AUTOSAR XML (schema 4-0-3)
standard types defined: UInt8
package /AUTOSAR_Platform/DataConstrs
  range DC_UInt8: raw 0..255
package /PATAC/MSM/ComponentTypes
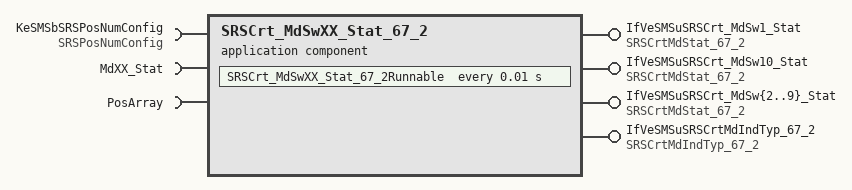
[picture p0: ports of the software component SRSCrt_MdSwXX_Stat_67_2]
  application sw component type SRSCrt_MdSwXX_Stat_67_2
    11 x provide port:
      IfVeSMSuSRSCrt_MdSw1_Stat: nonqueued-sender-com-spec=data-element=SRSCrtMdStat_67_2/Val, provided-interface=SRSCrtMdStat_67_2
      IfVeSMSuSRSCrt_MdSw10_Stat: nonqueued-sender-com-spec=data-element=SRSCrtMdStat_67_2/Val, provided-interface=SRSCrtMdStat_67_2
      IfVeSMSuSRSCrt_MdSw{2..9}_Stat: nonqueued-sender-com-spec=data-element=SRSCrtMdStat_67_2/Val, provided-interface=SRSCrtMdStat_67_2
      IfVeSMSuSRSCrtMdIndTyp_67_2: nonqueued-sender-com-spec=data-element=SRSCrtMdIndTyp_67_2/Val, provided-interface=SRSCrtMdIndTyp_67_2
    require port KeSMSbSRSPosNumConfig: parameter-require-com-spec{init-value=4, parameter=Val}, required-interface=SRSPosNumConfig
    require port MdXX_Stat: required-interface=MdXX_Stat
      required-com-specs:
        data-element=Md1_Stat, filter=data-filter-type=ALWAYS, init-value=0
        data-element=Md{10..19}_Stat, filter=data-filter-type=ALWAYS, init-value=0
        data-element=Md2_Stat, filter=data-filter-type=ALWAYS, init-value=0
        data-element=Md{20..29}_Stat, filter=data-filter-type=ALWAYS, init-value=0
        data-element=Md3_Stat, filter=data-filter-type=ALWAYS, init-value=0
        data-element=Md{30..32}_Stat, filter=data-filter-type=ALWAYS, init-value=0
        data-element=Md{4..9}_Stat, filter=data-filter-type=ALWAYS, init-value=0
    require port PosArray: nonqueued-receiver-com-spec{data-element=PosArray/Val, filter=data-filter-type=ALWAYS, init-value=11 x 0}, required-interface=PosArray
    behavior SRSCrt_MdSwXX_Stat_67_2_InternalBehavior
      timing event TMT_SRSCrt_MdSwXX_Stat_67_2Runnable: start-on-event=SRSCrt_MdSwXX_Stat_67_2Runnable, period=0.01
      runnable SRSCrt_MdSwXX_Stat_67_2Runnable
        data-receive-point-by-arguments:
          33 x access:
            REC_MdXX_Stat_Md1_Stat: accessed-variable=MdXX_Stat.Md1_Stat
            REC_MdXX_Stat_Md{10..19}_Stat: accessed-variable=MdXX_Stat.Md{10..19}_Stat
            REC_MdXX_Stat_Md2_Stat: accessed-variable=MdXX_Stat.Md2_Stat
            REC_MdXX_Stat_Md{20..29}_Stat: accessed-variable=MdXX_Stat.Md{20..29}_Stat
            REC_MdXX_Stat_Md3_Stat: accessed-variable=MdXX_Stat.Md3_Stat
            REC_MdXX_Stat_Md{30..32}_Stat: accessed-variable=MdXX_Stat.Md{30..32}_Stat
            REC_MdXX_Stat_Md{4..9}_Stat: accessed-variable=MdXX_Stat.Md{4..9}_Stat
            REC_PosArray_Val: accessed-variable=PosArray.Val
        data-send-points:
          11 x access:
            SEND_IfVeSMSuSRSCrt_MdSw1_Stat_Val: accessed-variable=IfVeSMSuSRSCrt_MdSw1_Stat.Val
            SEND_IfVeSMSuSRSCrt_MdSw10_Stat_Val: accessed-variable=IfVeSMSuSRSCrt_MdSw10_Stat.Val
            SEND_IfVeSMSuSRSCrt_MdSw{2..9}_Stat_Val: accessed-variable=IfVeSMSuSRSCrt_MdSw{2..9}_Stat.Val
            SEND_IfVeSMSuSRSCrtMdIndTyp_67_2_Val: accessed-variable=IfVeSMSuSRSCrtMdIndTyp_67_2.Val
        parameter access PA_KeSMSbSRSPosNumConfig_Val: accessed-parameter=KeSMSbSRSPosNumConfig.Val
  swc implementation SRSCrt_MdSwXX_Stat_67_2_Implementation: behavior=SRSCrt_MdSwXX_Stat_67_2_InternalBehavior
    code-descriptors:
      code Default: artifact-descriptors=autosar-engineering-object={short-label=Default, category=SWSRC}
package /PATAC/MSM/ModeAdjust/CalPortInterface
  parameter interface SRSPosNumConfig
    parameter data prototype Val: sw-calibration-access=READ-WRITE, type=UInt8
package /PATAC/MSM/ModeAdjust/DataType
  impl type ModeList: category=ARRAY, sw-calibration-access=READ-ONLY, type-emitter=RTE
    element Val: array-size=11, array-size-semantics=FIXED-SIZE, implementation-data-type=UInt8
package /PATAC/MSM/ModeAdjust/PortInterface
  4 x sender receiver interface:
    MdXX_Stat
      32 x data, all with type=UInt8:
        Md1_Stat
        Md{10..19}_Stat
        Md2_Stat
        Md{20..29}_Stat
        Md3_Stat
        Md{30..32}_Stat
        Md{4..9}_Stat
      invalidation-policys:
        data-element=Md{1..3}_Stat, handle-invalid=DONT-INVALIDATE
        data-element=Md5_Stat, handle-invalid=DONT-INVALIDATE
        data-element=Md4_Stat, handle-invalid=DONT-INVALIDATE
        data-element=Md12_Stat, handle-invalid=DONT-INVALIDATE
        data-element=Md6_Stat, handle-invalid=DONT-INVALIDATE
        data-element=Md15_Stat, handle-invalid=DONT-INVALIDATE
        data-element=Md7_Stat, handle-invalid=DONT-INVALIDATE
        data-element=Md13_Stat, handle-invalid=DONT-INVALIDATE
        data-element=Md8_Stat, handle-invalid=DONT-INVALIDATE
        data-element=Md18_Stat, handle-invalid=DONT-INVALIDATE
        data-element=Md9_Stat, handle-invalid=DONT-INVALIDATE
        data-element=Md14_Stat, handle-invalid=DONT-INVALIDATE
        data-element=Md10_Stat, handle-invalid=DONT-INVALIDATE
        data-element=Md16_Stat, handle-invalid=DONT-INVALIDATE
        data-element=Md11_Stat, handle-invalid=DONT-INVALIDATE
        data-element=Md20_Stat, handle-invalid=DONT-INVALIDATE
        data-element=Md17_Stat, handle-invalid=DONT-INVALIDATE
        data-element=Md19_Stat, handle-invalid=DONT-INVALIDATE
        data-element=Md22_Stat, handle-invalid=DONT-INVALIDATE
        data-element=Md21_Stat, handle-invalid=DONT-INVALIDATE
        data-element=Md24_Stat, handle-invalid=DONT-INVALIDATE
        data-element=Md23_Stat, handle-invalid=DONT-INVALIDATE
        data-element=Md26_Stat, handle-invalid=DONT-INVALIDATE
        data-element=Md25_Stat, handle-invalid=DONT-INVALIDATE
        data-element=Md28_Stat, handle-invalid=DONT-INVALIDATE
        data-element=Md27_Stat, handle-invalid=DONT-INVALIDATE
        data-element=Md30_Stat, handle-invalid=DONT-INVALIDATE
        data-element=Md29_Stat, handle-invalid=DONT-INVALIDATE
        data-element=Md32_Stat, handle-invalid=DONT-INVALIDATE
        data-element=Md31_Stat, handle-invalid=DONT-INVALIDATE
    PosArray: invalidation-policy{data-element=PosArray/Val, handle-invalid=DONT-INVALIDATE}
      data Val: type=ModeList
    SRSCrtMdIndTyp_67_2: invalidation-policy{data-element=SRSCrtMdIndTyp_67_2/Val, handle-invalid=DONT-INVALIDATE}
      data Val: type=UInt8
    SRSCrtMdStat_67_2: invalidation-policy{data-element=SRSCrtMdStat_67_2/Val, handle-invalid=DONT-INVALIDATE}
      data Val: type=UInt8
